# ESP32S31_RADIO register map
Vendor: Espressif; Series: ESP32-S31; File version: 3.52
Registers are 32-bit, read-write, no defined reset value unless marked. A register's access mark holds for its fields unless they carry their own. Offsets are from the block's base; [hi:lo] are bit positions; {n}, {i} and the like mark numbered series.

## BLE_HW_POSITIONAL_WORD_891C — Narrow owner for the otherwise isolated word at 0x2010891C. Complete ESP32-S31 BLE PHY initialization writes complete image 0x20 before initializing the BLE hardware accelerator and complete image 0x40 after the surrounding BTMAC and accelerator sequence. The register's physical block, hardware action and the meanings of the two images remain unproved, so no neighboring 0x201088xx words are absorbed.
Base 0x2010891C
0x00 VALUE wo — Complete ordered images 0x20 then 0x40 around BLE accelerator initialization; their hardware meaning remains unknown.
  [31:0] POSITIONAL_IMAGE — Complete positional image; only the ordered 0x20-then-0x40 publications are proven.

## BLE_CONTROLLER_ADDRESS_SLOTS — Three positional six-byte controller address slots. A complete ESP32-S31 ble_phy.c leaf proves the selector range, pair stride, byte packing and write order. Named callers identify public-address use of slot zero and random-address use of slot one; slot two remains intentionally unnamed.
Base 0x2010180C
{0x0+8i} SLOT{i}_LOW (i=0..2) wo — Bytes zero through three of the selected six-byte value, packed in little-endian order and written before the paired high word.
  [31:0] OCTETS_0_TO_3 — The complete low word assembled from input bytes zero through three.
{0x4+8i} SLOT{i}_HIGH (i=0..2) wo — Bytes four and five of the selected six-byte value in bits 0..15; the complete write clears bits 16..31.
  [15:0] OCTETS_4_TO_5 — Input bytes four and five packed in little-endian order.

## BLE_HW_POSITIONAL_WORD_1874 — Narrow positional owner for one word at 0x20101874 written by six complete ble_hw.c paths. Neither the destination's hardware action nor the dynamic value's inner meaning is claimed.
Base 0x20101874
0x00 VALUE wo — Observed complete publications contain a dynamic value in bits 0..19 and zero in bits 20..31.
  [19:0] DYNAMIC_LOW_20_IMAGE — Dynamic low-twenty-bit image. Complete writes clear bits 20..31; no pointer, index, queue or event semantic is established.

## BLE_SYNC_PUBLICATION — Two positional write-only words used by one ble_lll_sync.c path. The source identity records software context only; the register names deliberately do not turn that context into an undocumented hardware meaning.
Base 0x20101878
0x00 VALUE_0 wo — One runtime-derived complete 32-bit image.
  [31:0] IMAGE
0x04 VALUE_1 wo — One runtime-derived low-24-bit image; the complete publication writes bits 24..31 as zero.
  [23:0] IMAGE_LOW_24

## BLE_SCAN_CONTROL — Three positional complete images published by one ble_lll_scan.c path. The source file establishes scan-path ownership, but the undocumented hardware actions represented by the images remain unknown.
Base 0x20101970
0x00 COMMAND_0 wo — The observed path publishes the finite complete images 0x00000100 and 0x00000001 at different points.
  [31:0] IMAGE
0x04 COMMAND_1 wo — Both observed publications write the finite complete image one.
  [31:0] IMAGE
0x08 COMMAND_2 wo — Both observed publications write the finite complete image one.
  [31:0] IMAGE

## BLE_HW_ACCELERATOR — Sparse ESP32-S31 BLE hardware-accelerator view. Complete ble_hw.c operations independently prove encryption and resolving-list engines in this physical block; complete BLE PHY initialization proves three additional initialization words. Cross-chip objects provide function identities only. Addresses, field geometry, values, ordering and predicates all come from ESP32-S31 bytes.
Base 0x20109800
0x00 INIT_CONFIG — BLE PHY initialization writes the complete finite image 0x000002F0. Inner semantics remain unknown.
  [31:0] IMAGE
0x04 ENCRYPT_START wo — r_ble_hw_encrypt_block writes the complete value 1 after publishing all encryption parameters.
  [31:0] COMMAND
0x08 ENCRYPT_CONFIG — r_ble_hw_encrypt_block writes the finite complete image 1 before publishing buffer pointers.
  [31:0] IMAGE
0x0C ENCRYPT_BLOCK_LENGTH — r_ble_hw_encrypt_block writes the finite complete image 16.
  [31:0] BYTES
{0x10+4i} ENCRYPT_KEY_WORD_{i} wo (i=0..3) — Little-endian word assembled from encryption-key argument bytes {4i} through {4i+3}.
  [31:0] IMAGE
0x20 ENCRYPT_INPUT_BUFFER_ADDRESS wo — Complete pointer image equal to the r_ble_hw_encrypt_block argument base plus 16.
0x24 ENCRYPT_OUTPUT_BUFFER_ADDRESS wo — Complete pointer image equal to the r_ble_hw_encrypt_block argument base plus 32.
0x80 RESOLV_SEARCH_START wo — r_ble_hw_resolv_list_search writes the complete finite image 1 after publishing its inputs.
  [31:0] COMMAND
0x88 RESOLV_LIST_ARGUMENT wo — Complete first argument published by r_ble_hw_resolv_list_search.
  [31:0] IMAGE
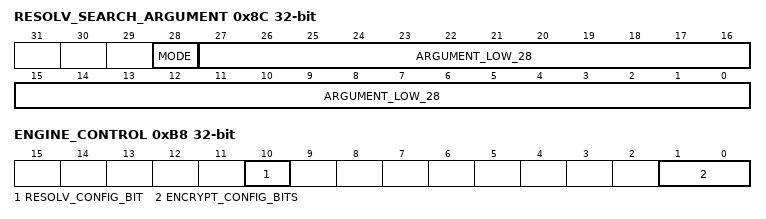
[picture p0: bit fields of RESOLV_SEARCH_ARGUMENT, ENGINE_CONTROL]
0x8C RESOLV_SEARCH_ARGUMENT wo — Second search argument in bits 0..27 and a Boolean third-argument mode in bit 28.
  [28] MODE, [27:0] ARGUMENT_LOW_28
0xA0 RESOLV_RESULT_METADATA ro — Search result word; r_ble_hw_resolv_list_search returns bits 8..15 through its fourth argument. Other bits remain unknown.
  [15:8] RESULT_BYTE
0xA4 RESOLV_RESULT_POINTER_OFFSET ro — Search result combined with SRAM prefix 0x2F000000 to form the returned pointer. The exact encoded width remains unknown.
  [31:0] IMAGE
0xA8 RESOLV_RESULT_PRESENT ro — Complete word tested for zero before the result pointer and metadata are consumed.
  [31:0] IMAGE
0xB8 ENGINE_CONTROL — Shared control word: encryption sets bits 0..1 through RMW; resolving-list search writes the finite complete image 0x400.
  [10] RESOLV_CONFIG_BIT, [1:0] ENCRYPT_CONFIG_BITS
0xBC RESOLV_STATUS ro — r_ble_hw_resolv_list_search polls bit 2 with a finite software timeout.
  [2] COMPLETE
0xC4 ENCRYPT_COMPLETION_STATUS ro — r_ble_hw_encrypt_block polls the complete word until nonzero, with a finite software timeout. Inner encoding remains unknown.
  [31:0] IMAGE
0xCC INIT_SRAM_REGION_0 — BLE PHY initialization writes the complete finite image 0x2F080000. Inner semantics remain unknown.
  [31:0] IMAGE
0xD0 INIT_SRAM_REGION_1 — BLE PHY initialization writes the complete finite image 0x2F000000. Inner semantics remain unknown.
  [31:0] IMAGE
